AUTOSAR XML (schema 4-3-0)
package /ComponentTypes
  swc implementation YDF_OutPutDriver_Implementation: behavior=YDF_OutPutDriver_InternalBehavior
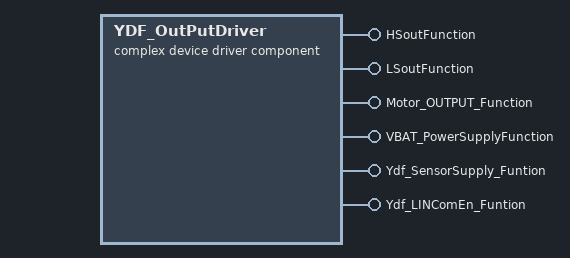
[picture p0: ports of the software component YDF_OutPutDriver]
  complex device driver sw component type YDF_OutPutDriver
    6 x provide port:
      HSoutFunction: provided-interface=HSoutFunction
        provided-com-specs:
          operation=High_Side{1..4}_Function, queue-length=1
      LSoutFunction: provided-interface=LSoutFunction
        provided-com-specs:
          operation=Lowout{1..4}_Function, queue-length=1
          operation=Lowout20_Function, queue-length=1
          operation=Lowout{22..24}_Function, queue-length=1
          operation=Lowout_Lamp1_Function, queue-length=1
          operation=Lowout_Lamp2_Function, queue-length=1
          operation=Lowout_PWMOUT1_Function, queue-length=1
          operation=Lowout_PWMOUT2_Function, queue-length=1
          operation=Lowout{5..19}_Function, queue-length=1
          operation=Lowout21_Function, queue-length=1
      Motor_OUTPUT_Function: server-com-spec{operation=App_Motor_OUTPUT_Function, queue-length=1}, provided-interface=Motor_OUTPUT_Function
      VBAT_PowerSupplyFunction: provided-com-specs=[{operation=D_VBAT_A_OFF, queue-length=1}, {operation=D_VBAT_B_OFF, queue-length=1}], provided-interface=VBAT_PowerSupplyFunction
      Ydf_SensorSupply_Funtion: provided-interface=Ydf_SensorSupply_Funtion
        provided-com-specs:
          operation=SensorSupply3_5v_OUT_Enable, queue-length=1
          operation=SensorSupply4_5v_OUT_Enable, queue-length=1
      Ydf_LINComEn_Funtion: provided-interface=Ydf_LINComEn_Funtion
        provided-com-specs:
          operation=LINB_OUT_Enable, queue-length=1
          operation=LINC_OUT_Enable, queue-length=1
          operation=LIND_OUT_Enable, queue-length=1
    behavior YDF_OutPutDriver_InternalBehavior
      40 x operation invoked event:
        OIT_HSoutFunction_High_Side4_Function_HSoutFunction_High_Side4_Function: start-on-event=HSoutFunction_High_Side4_Function, operation=HSoutFunction.High_Side4_Function
        OIT_HSoutFunction_High_Side3_Function_HSoutFunction_High_Side3_Function: start-on-event=HSoutFunction_High_Side3_Function, operation=HSoutFunction.High_Side3_Function
        OIT_HSoutFunction_High_Side2_Function_HSoutFunction_High_Side2_Function: start-on-event=HSoutFunction_High_Side2_Function, operation=HSoutFunction.High_Side2_Function
        OIT_HSoutFunction_High_Side1_Function_HSoutFunction_High_Side1_Function: start-on-event=HSoutFunction_High_Side1_Function, operation=HSoutFunction.High_Side1_Function
        OIT_LSoutFunction_Lowout21_Function_LSoutFunction_Lowout21_Function: start-on-event=LSoutFunction_Lowout21_Function, operation=LSoutFunction.Lowout21_Function
        OIT_LSoutFunction_Lowout19_Function_LSoutFunction_Lowout19_Function: start-on-event=LSoutFunction_Lowout19_Function, operation=LSoutFunction.Lowout19_Function
        OIT_LSoutFunction_Lowout18_Function_LSoutFunction_Lowout18_Function: start-on-event=LSoutFunction_Lowout18_Function, operation=LSoutFunction.Lowout18_Function
        OIT_LSoutFunction_Lowout17_Function_LSoutFunction_Lowout17_Function: start-on-event=LSoutFunction_Lowout17_Function, operation=LSoutFunction.Lowout17_Function
        OIT_LSoutFunction_Lowout16_Function_LSoutFunction_Lowout16_Function: start-on-event=LSoutFunction_Lowout16_Function, operation=LSoutFunction.Lowout16_Function
        OIT_LSoutFunction_Lowout15_Function_LSoutFunction_Lowout15_Function: start-on-event=LSoutFunction_Lowout15_Function, operation=LSoutFunction.Lowout15_Function
        OIT_LSoutFunction_Lowout14_Function_LSoutFunction_Lowout14_Function: start-on-event=LSoutFunction_Lowout14_Function, operation=LSoutFunction.Lowout14_Function
        OIT_LSoutFunction_Lowout13_Function_LSoutFunction_Lowout13_Function: start-on-event=LSoutFunction_Lowout13_Function, operation=LSoutFunction.Lowout13_Function
        OIT_LSoutFunction_Lowout12_Function_LSoutFunction_Lowout12_Function: start-on-event=LSoutFunction_Lowout12_Function, operation=LSoutFunction.Lowout12_Function
        OIT_LSoutFunction_Lowout11_Function_LSoutFunction_Lowout11_Function: start-on-event=LSoutFunction_Lowout11_Function, operation=LSoutFunction.Lowout11_Function
        OIT_LSoutFunction_Lowout10_Function_LSoutFunction_Lowout10_Function: start-on-event=LSoutFunction_Lowout10_Function, operation=LSoutFunction.Lowout10_Function
        OIT_LSoutFunction_Lowout9_Function_LSoutFunction_Lowout9_Function: start-on-event=LSoutFunction_Lowout9_Function, operation=LSoutFunction.Lowout9_Function
        OIT_LSoutFunction_Lowout8_Function_LSoutFunction_Lowout8_Function: start-on-event=LSoutFunction_Lowout8_Function, operation=LSoutFunction.Lowout8_Function
        OIT_LSoutFunction_Lowout7_Function_LSoutFunction_Lowout7_Function: start-on-event=LSoutFunction_Lowout7_Function, operation=LSoutFunction.Lowout7_Function
        OIT_LSoutFunction_Lowout6_Function_LSoutFunction_Lowout6_Function: start-on-event=LSoutFunction_Lowout6_Function, operation=LSoutFunction.Lowout6_Function
        OIT_LSoutFunction_Lowout5_Function_LSoutFunction_Lowout5_Function: start-on-event=LSoutFunction_Lowout5_Function, operation=LSoutFunction.Lowout5_Function
        OIT_LSoutFunction_Lowout_PWMOUT2_Function_LSoutFunction_Lowout_PWMOUT2_Function: start-on-event=LSoutFunction_Lowout_PWMOUT2_Function, operation=LSoutFunction.Lowout_PWMOUT2_Function
        OIT_LSoutFunction_Lowout_PWMOUT1_Function_LSoutFunction_Lowout_PWMOUT1_Function: start-on-event=LSoutFunction_Lowout_PWMOUT1_Function, operation=LSoutFunction.Lowout_PWMOUT1_Function
        OIT_LSoutFunction_Lowout_Lamp2_Function_LSoutFunction_Lowout_Lamp2_Function: start-on-event=LSoutFunction_Lowout_Lamp2_Function, operation=LSoutFunction.Lowout_Lamp2_Function
        OIT_LSoutFunction_Lowout_Lamp1_Function_LSoutFunction_Lowout_Lamp1_Function: start-on-event=LSoutFunction_Lowout_Lamp1_Function, operation=LSoutFunction.Lowout_Lamp1_Function
        OIT_LSoutFunction_Lowout24_Function_LSoutFunction_Lowout24_Function: start-on-event=LSoutFunction_Lowout24_Function, operation=LSoutFunction.Lowout24_Function
        OIT_LSoutFunction_Lowout23_Function_LSoutFunction_Lowout23_Function: start-on-event=LSoutFunction_Lowout23_Function, operation=LSoutFunction.Lowout23_Function
        OIT_LSoutFunction_Lowout22_Function_LSoutFunction_Lowout22_Function: start-on-event=LSoutFunction_Lowout22_Function, operation=LSoutFunction.Lowout22_Function
        OIT_LSoutFunction_Lowout20_Function_LSoutFunction_Lowout20_Function: start-on-event=LSoutFunction_Lowout20_Function, operation=LSoutFunction.Lowout20_Function
        OIT_LSoutFunction_Lowout4_Function_LSoutFunction_Lowout4_Function: start-on-event=LSoutFunction_Lowout4_Function, operation=LSoutFunction.Lowout4_Function
        OIT_LSoutFunction_Lowout3_Function_LSoutFunction_Lowout3_Function: start-on-event=LSoutFunction_Lowout3_Function, operation=LSoutFunction.Lowout3_Function
        OIT_LSoutFunction_Lowout2_Function_LSoutFunction_Lowout2_Function: start-on-event=LSoutFunction_Lowout2_Function, operation=LSoutFunction.Lowout2_Function
        OIT_LSoutFunction_Lowout1_Function_LSoutFunction_Lowout1_Function: start-on-event=LSoutFunction_Lowout1_Function, operation=LSoutFunction.Lowout1_Function
        OIT_Motor_OUTPUT_Function_App_Motor_OUTPUT_Function_Motor_OUTPUT_Function_App_Motor_OUTPUT_Function: start-on-event=Motor_OUTPUT_Function_App_Motor_OUTPUT_Function, operation=Motor_OUTPUT_Function.App_Motor_OUTPUT_Function
        OIT_VBAT_PowerSupplyFunction_D_VBAT_B_OFF_VBAT_PowerSupplyFunction_D_VBAT_B_OFF: start-on-event=VBAT_PowerSupplyFunction_D_VBAT_B_OFF, operation=VBAT_PowerSupplyFunction.D_VBAT_B_OFF
        OIT_VBAT_PowerSupplyFunction_D_VBAT_A_OFF_VBAT_PowerSupplyFunction_D_VBAT_A_OFF: start-on-event=VBAT_PowerSupplyFunction_D_VBAT_A_OFF, operation=VBAT_PowerSupplyFunction.D_VBAT_A_OFF
        OIT_Ydf_SensorSupply_Funtion_SensorSupply4_5v_OUT_Enable_Ydf_SensorSupply_Funtion_SensorSupply4_5v_OUT_Enable: start-on-event=Ydf_SensorSupply_Funtion_SensorSupply4_5v_OUT_Enable, operation=Ydf_SensorSupply_Funtion.SensorSupply4_5v_OUT_Enable
        OIT_Ydf_SensorSupply_Funtion_SensorSupply3_5v_OUT_Enable_Ydf_SensorSupply_Funtion_SensorSupply3_5v_OUT_Enable: start-on-event=Ydf_SensorSupply_Funtion_SensorSupply3_5v_OUT_Enable, operation=Ydf_SensorSupply_Funtion.SensorSupply3_5v_OUT_Enable
        OIT_Ydf_LINComEn_Funtion_LIND_OUT_Enable_Ydf_LINComEn_Funtion_LIND_OUT_Enable: start-on-event=Ydf_LINComEn_Funtion_LIND_OUT_Enable, operation=Ydf_LINComEn_Funtion.LIND_OUT_Enable
        OIT_Ydf_LINComEn_Funtion_LINC_OUT_Enable_Ydf_LINComEn_Funtion_LINC_OUT_Enable: start-on-event=Ydf_LINComEn_Funtion_LINC_OUT_Enable, operation=Ydf_LINComEn_Funtion.LINC_OUT_Enable
        OIT_Ydf_LINComEn_Funtion_LINB_OUT_Enable_Ydf_LINComEn_Funtion_LINB_OUT_Enable: start-on-event=Ydf_LINComEn_Funtion_LINB_OUT_Enable, operation=Ydf_LINComEn_Funtion.LINB_OUT_Enable
      40 x runnable:
        HSoutFunction_High_Side4_Function
        HSoutFunction_High_Side3_Function
        HSoutFunction_High_Side2_Function
        HSoutFunction_High_Side1_Function
        LSoutFunction_Lowout21_Function
        LSoutFunction_Lowout19_Function
        LSoutFunction_Lowout18_Function
        LSoutFunction_Lowout17_Function
        LSoutFunction_Lowout16_Function
        LSoutFunction_Lowout15_Function
        LSoutFunction_Lowout14_Function
        LSoutFunction_Lowout13_Function
        LSoutFunction_Lowout12_Function
        LSoutFunction_Lowout11_Function
        LSoutFunction_Lowout10_Function
        LSoutFunction_Lowout9_Function
        LSoutFunction_Lowout8_Function
        LSoutFunction_Lowout7_Function
        LSoutFunction_Lowout6_Function
        LSoutFunction_Lowout5_Function
        LSoutFunction_Lowout_PWMOUT2_Function
        LSoutFunction_Lowout_PWMOUT1_Function
        LSoutFunction_Lowout_Lamp2_Function
        LSoutFunction_Lowout_Lamp1_Function
        LSoutFunction_Lowout24_Function
        LSoutFunction_Lowout23_Function
        LSoutFunction_Lowout22_Function
        LSoutFunction_Lowout20_Function
        LSoutFunction_Lowout4_Function
        LSoutFunction_Lowout3_Function
        LSoutFunction_Lowout2_Function
        LSoutFunction_Lowout1_Function
        Motor_OUTPUT_Function_App_Motor_OUTPUT_Function
        VBAT_PowerSupplyFunction_D_VBAT_B_OFF
        VBAT_PowerSupplyFunction_D_VBAT_A_OFF
        Ydf_SensorSupply_Funtion_SensorSupply4_5v_OUT_Enable
        Ydf_SensorSupply_Funtion_SensorSupply3_5v_OUT_Enable
        Ydf_LINComEn_Funtion_LIND_OUT_Enable
        Ydf_LINComEn_Funtion_LINC_OUT_Enable
        Ydf_LINComEn_Funtion_LINB_OUT_Enable
